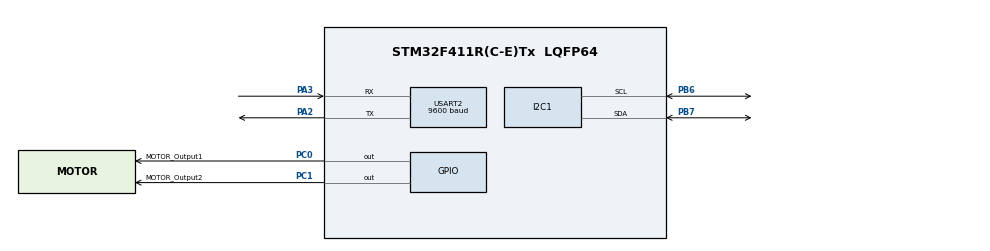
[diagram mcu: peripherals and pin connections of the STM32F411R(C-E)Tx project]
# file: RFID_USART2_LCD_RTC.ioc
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Mcu.Family=STM32F4
Mcu.Name=STM32F411R(C-E)Tx
Mcu.Package=LQFP64
NVIC.PriorityGroup=NVIC_PRIORITYGROUP_4
NVIC.USART2_IRQn=true\:0\:0\:false\:false\:true\:true\:true\:true
PA2.Mode=Asynchronous
PA2.Signal=USART2_TX
PA3.Mode=Asynchronous
PA3.Signal=USART2_RX
PB6.Mode=I2C
PB6.Signal=I2C1_SCL
PB7.Mode=I2C
PB7.Signal=I2C1_SDA
PC0.GPIO_Label=MOTOR_Output1
PC0.Signal=GPIO_Output
PC1.GPIO_Label=MOTOR_Output2
PC1.Signal=GPIO_Output
ProjectManager.HeapSize=0x200
ProjectManager.StackSize=0x400
ProjectManager.TargetToolchain=STM32CubeIDE
RCC.AHBFreq_Value=16000000
RCC.APB1Freq_Value=16000000
RCC.APB2Freq_Value=16000000
RCC.CortexFreq_Value=16000000
RCC.HSE_VALUE=25000000
RCC.HSI_VALUE=16000000
RCC.LSE_VALUE=32768
RCC.SYSCLKFreq_VALUE=16000000
RCC.VCOOutputFreq_Value=192000000
RTC.Date=27
RTC.Format=RTC_FORMAT_BIN
RTC.Hours=12
RTC.Minutes=59
RTC.Month=RTC_MONTH_DECEMBER
RTC.Seconds=45
RTC.WeekDay=RTC_WEEKDAY_SUNDAY
USART2.BaudRate=9600
USART2.VirtualMode=VM_ASYNC
VP_RTC_VS_RTC_Activate.Mode=RTC_Enabled
VP_RTC_VS_RTC_Calendar.Mode=RTC_Calendar
board=custom

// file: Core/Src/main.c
/* USER CODE BEGIN Header */
/**
  ******************************************************************************
  * @file           : main.c
  * @brief          : Main program body
  ******************************************************************************
  * @attention
  *
  * Copyright (c) 2022 STMicroelectronics.
  * All rights reserved.
  *
  * This software is licensed under terms that can be found in the LICENSE file
  * in the root directory of this software component.
  * If no LICENSE file comes with this software, it is provided AS-IS.
  *
  ******************************************************************************
  */
/* USER CODE END Header */
#include<stdio.h>
#include "main.h"
#include<string.h>
#include"lcd.h"
#include"RTC.h"

I2C_HandleTypeDef hi2c1;

RTC_HandleTypeDef hrtc;
RTC_TimeTypeDef sTime;
RTC_DateTypeDef sDate;

UART_HandleTypeDef huart2;

/* USER CODE BEGIN PV */
void MOTOR_Init(void);

/* USER CODE END PV */

void SystemClock_Config(void);
static void MX_GPIO_Init(void);
static void MX_I2C1_Init(void);
static void MX_RTC_Init(void);
static void MX_USART2_UART_Init(void);
/* USER CODE BEGIN PFP */
#define TRUE 1
#define FALSE 0
/* USER CODE END PFP */

/* USER CODE BEGIN 0 */
char *USER_DATA="Sankalp!";
uint8_t recvd_data;
	uint8_t Data_Buffer[50];
	uint8_t count=0;
	uint8_t rec_comp_data=FALSE;
	char str[20];
	char *buffer[15];
/* USER CODE END 0 */

int main(void)
{

  /* MCU Configuration--------------------------------------------------------*/

  /* Reset of all peripherals, Initializes the Flash interface and the Systick. */
  HAL_Init();
  LCD_init();

  /* Configure the system clock */
  SystemClock_Config();

  /* Initialize all configured peripherals */
  MX_GPIO_Init();
  MX_I2C1_Init();
  MX_RTC_Init();
  MX_USART2_UART_Init();
  HAL_UART_Transmit(&huart2, (uint8_t *)USER_DATA, strlen(USER_DATA), HAL_MAX_DELAY);
  uint32_t count = 0;

  /* Infinite loop */
  /* USER CODE BEGIN WHILE */
	while(1)
	{
		HAL_UART_Receive(&huart2, &recvd_data, 1, HAL_MAX_DELAY);    //Read byte by byte

		if(recvd_data == '\0')
		{
			//detect Return/Enter key
			Data_Buffer[count++] = '\0';
			break;
		}
		else
		{
//			Data_Buffer[count++] = Convert_To_Upper(recvd_data);
			Data_Buffer[count++] = recvd_data;
		}
	}

	HAL_UART_Transmit(&huart2, (uint8_t*)Data_Buffer, count, HAL_MAX_DELAY);
  /* USER CODE END 3 */
	if(strcmp(Data_Buffer,"18")==0)
	{
		LCD_command(1);
		LCD_string("WELCOME ON BOARD");
		LCD_command(0xC4);
		LCD_string("SANKALP!");
		LCD_command(1);
		LCD_string("LOGIN TIME");
		LCD_command(0xC4);
		LCD_string(buffer1);
		MOTOR_Init();
	}
	else if(strcmp(Data_Buffer,"3E")==0)
	{
		LCD_command(1);
		LCD_string("WELCOME ON BOARD");
		LCD_command(0xC4);
		LCD_string("NARESH!");
		MOTOR_Init();
	}
	else if(strcmp(Data_Buffer,"55")==0)
	{
		LCD_command(1);
		LCD_string("WELCOME ON BOARD");
		LCD_command(0xC4);
		LCD_string("SANDEEP!");
		MOTOR_Init();

	}
}

void MOTOR_Init()
{
	HAL_GPIO_WritePin(GPIOC, GPIO_PIN_0, 1);       //For Gate Open
	HAL_GPIO_WritePin(GPIOC, GPIO_PIN_1, 0);
	delay(3000);
	HAL_GPIO_WritePin(GPIOC, GPIO_PIN_0, 0);        //Stop
	HAL_GPIO_WritePin(GPIOC, GPIO_PIN_1, 0);
	delay(2000);
	HAL_GPIO_WritePin(GPIOC, GPIO_PIN_0, 0);       //For Gate Close
	HAL_GPIO_WritePin(GPIOC, GPIO_PIN_1, 1);
	delay(3000);
	HAL_GPIO_WritePin(GPIOC, GPIO_PIN_0, 0);        //Stop
	HAL_GPIO_WritePin(GPIOC, GPIO_PIN_1, 0);
	LCD_command(1);
}

static void MX_USART2_UART_Init(void)
{

  huart2.Instance = USART2;
  huart2.Init.BaudRate = 9600;
  huart2.Init.WordLength = UART_WORDLENGTH_8B;
  huart2.Init.StopBits = UART_STOPBITS_1;
  huart2.Init.Parity = UART_PARITY_NONE;
  huart2.Init.Mode = UART_MODE_TX_RX;
  huart2.Init.HwFlowCtl = UART_HWCONTROL_NONE;
  huart2.Init.OverSampling = UART_OVERSAMPLING_16;
  if (HAL_UART_Init(&huart2) != HAL_OK)
  {
    Error_Handler();
  }

}

static void MX_GPIO_Init(void)
{
  GPIO_InitTypeDef GPIO_InitStruct = {0};

  /* GPIO Ports Clock Enable */
  __HAL_RCC_GPIOC_CLK_ENABLE();
  __HAL_RCC_GPIOA_CLK_ENABLE();
  __HAL_RCC_GPIOB_CLK_ENABLE();

  /*Configure GPIO pin Output Level */
  HAL_GPIO_WritePin(GPIOC, MOTOR_Output1_Pin|MOTOR_Output2_Pin, GPIO_PIN_RESET);

  /*Configure GPIO pins : MOTOR_Output1_Pin MOTOR_Output2_Pin */
  GPIO_InitStruct.Pin = MOTOR_Output1_Pin|MOTOR_Output2_Pin;
  GPIO_InitStruct.Mode = GPIO_MODE_OUTPUT_PP;
  GPIO_InitStruct.Pull = GPIO_NOPULL;
  GPIO_InitStruct.Speed = GPIO_SPEED_FREQ_LOW;
  HAL_GPIO_Init(GPIOC, &GPIO_InitStruct);

}

void Error_Handler(void)
{
  __disable_irq();
  while (1)
  {
  }
}
